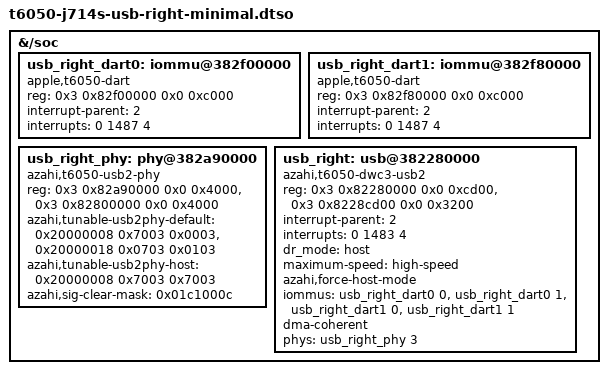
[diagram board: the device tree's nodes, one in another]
/dts-v1/;
/plugin/;

/*
 * Runtime overlay: right-hand USB-C socket of the J714s (ADT instance 2,
 * port-number 3, SPMI hpm2 port-location "right"), USB2 host only.
 *
 * MINIMAL variant: no PMGR power-domain nodes and no reset provider. It relies
 * on the m1n1-based loader's usb_phy_bringup(2), which powers ATC2_COMMON /
 * ATC2_USB_AON / ATC2_USB / ATC2_PHYMXWRAP / dart-usb2 and leaves the DWC3
 * out of reset with the PIPE mux on the dummy PHY. The loader module verifies
 * the PMGR state (read-only) before applying this overlay.
 *
 * Numeric phandle 2 is the AIC in the installed rootguard DTB
 * (t6050-j714s-native-rootguard.dtb, /soc/interrupt-controller@280400000);
 * the live tree has no __symbols__, so labels cannot be used for it. The
 * loader module checks that phandle at run time before applying.
 *
 * Every address below is the ADT-translated value from adt-real-t6050.bin
 * (probe/network-hardware-audit.py, usb-driver/README.md).
 */

/ {
	fragment@0 {
		target-path = "/soc";
		__overlay__ {
			usb_right_dart0: iommu@382f00000 {
				compatible = "apple,t6050-dart", "apple,t8110-dart";
				reg = <0x3 0x82f00000 0x0 0xc000>;
				interrupt-parent = <2>;
				interrupts = <0 1487 4>;
				#iommu-cells = <1>;
			};

			usb_right_dart1: iommu@382f80000 {
				compatible = "apple,t6050-dart", "apple,t8110-dart";
				reg = <0x3 0x82f80000 0x0 0xc000>;
				interrupt-parent = <2>;
				interrupts = <0 1487 4>;
				#iommu-cells = <1>;
			};

			usb_right_phy: phy@382a90000 {
				compatible = "azahi,t6050-usb2-phy";
				reg = <0x3 0x82a90000 0x0 0x4000>,
				      <0x3 0x82800000 0x0 0x4000>;
				reg-names = "usb2phy", "usb2evt";
				#phy-cells = <1>;
				/* ADT atc-phy2 tunable_USB2PHY_DFLT: +0x8 mask 0x7003 -> 0x0003, +0x18 mask 0x703 -> 0x103 */
				azahi,tunable-usb2phy-default = <0x20000008 0x7003 0x0003>,
								<0x20000018 0x0703 0x0103>;
				/* ADT atc-phy2 tunable_USB2PHY_HOST: +0x8 mask 0x7003 -> 0x7003 */
				azahi,tunable-usb2phy-host = <0x20000008 0x7003 0x7003>;
				/* loader device-mode bits (0x01c1000f) not set by the M5 host path */
				azahi,sig-clear-mask = <0x01c1000c>;
			};

			usb_right: usb@382280000 {
				compatible = "azahi,t6050-dwc3-usb2";
				reg = <0x3 0x82280000 0x0 0xcd00>,
				      <0x3 0x8228cd00 0x0 0x3200>;
				reg-names = "dwc3-core", "dwc3-apple";
				interrupt-parent = <2>;
				interrupts = <0 1483 4>;
				dr_mode = "host";
				maximum-speed = "high-speed";
				azahi,force-host-mode;
				/* ADT mapper-usb2 SID 1; upstream Apple DTs use dart0 SID 0 + dart1 SID 1. Map both on both. */
				iommus = <&usb_right_dart0 0>, <&usb_right_dart0 1>,
					 <&usb_right_dart1 0>, <&usb_right_dart1 1>;
				dma-coherent;
				phys = <&usb_right_phy 3>;	/* PHY_TYPE_USB2 == 3 in this kernel's dt-bindings */
				phy-names = "usb2-phy";
			};
		};
	};
};
